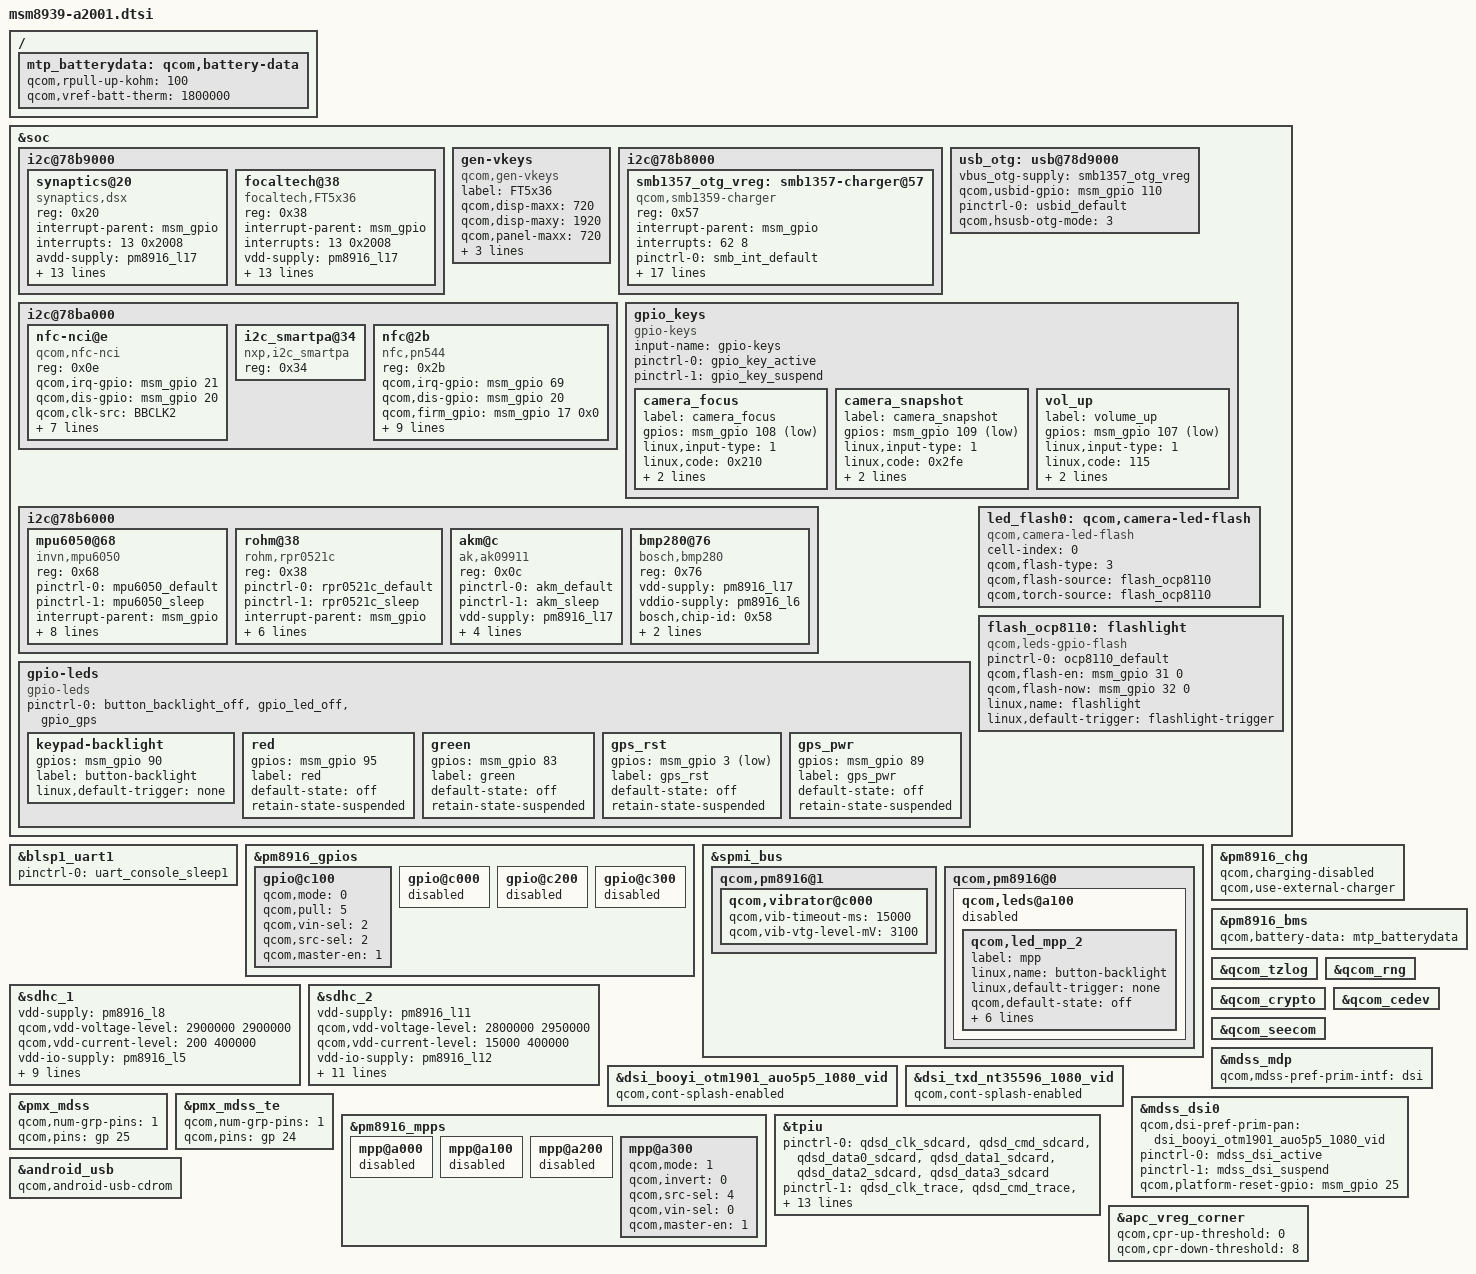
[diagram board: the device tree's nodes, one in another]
/* Copyright (c) 2014-2015, The Linux Foundation. All rights reserved.
 *
 * This program is free software; you can redistribute it and/or modify
 * it under the terms of the GNU General Public License version 2 and
 * only version 2 as published by the Free Software Foundation.
 *
 * This program is distributed in the hope that it will be useful,
 * but WITHOUT ANY WARRANTY; without even the implied warranty of
 * MERCHANTABILITY or FITNESS FOR A PARTICULAR PURPOSE.  See the
 * GNU General Public License for more details.
 */

#include "msm8939-pinctrl-a2001.dtsi"
//#include "msm8939-camera-sensor-mtp.dtsi"
#include "ehang_camera_a2001.dtsi"

&soc {
	i2c@78b9000 { /* BLSP1 QUP5 */
		synaptics@20 {
			compatible = "synaptics,dsx";
			reg = <0x20>;
			interrupt-parent = <&msm_gpio>;
			interrupts = <13 0x2008>;
			avdd-supply = <&pm8916_l17>;
			vdd-supply = <&pm8916_l6>;
			/* pins used by touchscreen */
			pinctrl-names = "pmx_ts_active","pmx_ts_suspend","pmx_ts_suspend";
			pinctrl-0 = <&ts_int_active &ts_reset_active>;
			pinctrl-1 = <&ts_int_suspend &ts_reset_suspend>;
			pinctrl-2 = <&ts_release>;
			synaptics,irq-gpio = <&msm_gpio 13 0x2008>;
			synaptics,reset-gpio = <&msm_gpio 12 0x0>;
			synaptics,i2c-pull-up;
			synaptics,power-down;
			synaptics,disable-gpios;
			synaptics,display-coords = <0 0 1079 1919>;
			synaptics,panel-coords = <0 0 1079 2084>;
			/* Underlying clocks used by secure touch */
			clocks = <&clock_gcc clk_gcc_blsp1_ahb_clk>,
			 <&clock_gcc clk_gcc_blsp1_qup5_i2c_apps_clk>;
			clock-names = "iface_clk", "core_clk";
		};

		focaltech@38 {
			compatible = "focaltech,FT5x36";
			reg = <0x38>;
			interrupt-parent = <&msm_gpio>;
			interrupts = <13 0x2008>;
			vdd-supply = <&pm8916_l17>;
			vcc_i2c-supply = <&pm8916_l6>;
			pinctrl-names = "pmx_ts_active","pmx_ts_suspend";
			pinctrl-0 = <&ts_int_active &ts_reset_active>;
            /*Modified by jiao.shp for tp gesture in 20141113 START*/
            #if 0
			pinctrl-1 = <&ts_int_suspend &ts_reset_suspend>;
            #else
            pinctrl-1 = <&ts_int_active &ts_reset_suspend>;
            #endif
            /*Modified by jiao.shp for tp gesture in 20141113 END*/
			focaltech,family-id = <8>;
			focaltech,max_touch_point = <5>;
			focaltech,reset-gpio = <&msm_gpio 12 0x00>;
			focaltech,irq-gpio = <&msm_gpio 13 0x00>;
			focaltech,display-coords = <0 0 1080 1920>;
			focaltech,panel-coords = <0 0 1080 2020>;
			focaltech,button-map= <139 172 158>;
			focaltech,no-force-update;
			focaltech,i2c-pull-up;
			focaltech,auto_clb;
		};
	};
	gen-vkeys {
		compatible = "qcom,gen-vkeys";
		label = "FT5x36";
		qcom,disp-maxx = <720>;
		qcom,disp-maxy = <1920>;
		qcom,panel-maxx = <720>;
		qcom,panel-maxy = <2080>;
		qcom,key-codes = <139 172 158>;
		qcom,y-offset = <0>;
	};

	// by skj
	i2c@78b8000 {
		smb1357_otg_vreg: smb1357-charger@57 {
			compatible = "qcom,smb1359-charger";
			reg = <0x57>;
			interrupt-parent = <&msm_gpio>;
			interrupts = <62 8>;
			pinctrl-names = "default";
			pinctrl-0 = <&smb_int_default>;

			qcom,bmd-algo-disabled;
			// skj 2005
			qcom,float-voltage-mv = <4200>;
			qcom,charging-timeout = <1536>;
			qcom,recharge-thresh-mv = <100>;
			regulator-name = "smb1357_otg_vreg";
			qcom,soft-vfloat-comp-disabled;
			qcom,thermal-mitigation = <2500 700 600 0>;

			qcom,bms-psy-name = "bms";
			qcom,iterm-disabled;
			qcom,integrated-bms;
			qcom,inhibit-disabled;
			qcom,bms-controlled-charging;
			qcom,chg-vadc = <&pm8916_vadc>;
			qcom,pa-ctrl-pin = <&msm_gpio 93 0>;
			qcom,fastchg-ma= <1500>; 
			
			qcom,dc-psy-type = "Mains";
			qcom,dc-psy-ma = <800>;
			
		};
	};
	// by skj
	usb_otg: usb@78d9000 {
		vbus_otg-supply = <&smb1357_otg_vreg>;
		//vbus_otg-supply = <&pm8916_s1_corner>;
		qcom,usbid-gpio = <&msm_gpio 110 0>;
		pinctrl-names = "default";
		pinctrl-0 = <&usbid_default>;
		qcom,hsusb-otg-mode = <3>;
	};

	i2c@78ba000 { /* BLSP1 QUP6 */
		nfc-nci@e {
			compatible = "qcom,nfc-nci";
			reg = <0x0e>;
			qcom,irq-gpio = <&msm_gpio 21 0x00>;
			qcom,dis-gpio = <&msm_gpio 20 0x00>;
			qcom,clk-src = "BBCLK2";
			interrupt-parent = <&msm_gpio>;
			interrupts = <21 0>;
			interrupt-names = "nfc_irq";
			pinctrl-names = "nfc_active","nfc_suspend";
			pinctrl-0 = <&nfc_int_active &nfc_disable_active>;
			pinctrl-1 = <&nfc_int_suspend &nfc_disable_suspend>;
			qcom,clk-gpio = <&pm8916_gpios 2 0>;
			clocks = <&clock_rpm clk_bb_clk2_pin>;
			clock-names = "ref_clk";
		};
		i2c_smartpa@34 {
			compatible = "nxp,i2c_smartpa";
			reg = <0x34>;
		};
	};
	
	// by skj
	i2c@78ba000 { /* BLSP1 QUP6 */
		nfc@2b {
			compatible = "nfc,pn544";
			reg = <0x2b>;
			qcom,irq-gpio = <&msm_gpio 69 0x00>;
			qcom,dis-gpio = <&msm_gpio 20 0x00>;
			qcom,firm_gpio = <&msm_gpio 17 0x0>;
			qcom,clk-src = "BBCLK2";
			qcom,clk-en-gpio = <&msm_gpio 21 0x00>;
			interrupt-parent = <&msm_gpio>;
			interrupts = <69 0>;
			interrupt-names = "nfc_irq";
			pinctrl-names = "nfc_active","nfc_suspend";
			pinctrl-0 = <&nfc_int_active &nfc_disable_active>;
			pinctrl-1 = <&nfc_int_suspend &nfc_disable_suspend>;
			qcom,clk-gpio = <&pm8916_gpios 2 0>;
			clocks = <&clock_rpm clk_bb_clk2_pin>;
			clock-names = "ref_clk";
			};
	};
	
	
	gpio_keys {
		compatible = "gpio-keys";
		input-name = "gpio-keys";
		pinctrl-names = "tlmm_gpio_key_active","tlmm_gpio_key_suspend";
		pinctrl-0 = <&gpio_key_active>;
		pinctrl-1 = <&gpio_key_suspend>;

		camera_focus {
			label = "camera_focus";
			gpios = <&msm_gpio 108 0x1>;
			linux,input-type = <1>;
			linux,code = <0x210>;
			gpio-key,wakeup;
			debounce-interval = <15>;
		};

		camera_snapshot {
			label = "camera_snapshot";
			gpios = <&msm_gpio 109 0x1>;
			linux,input-type = <1>;
			linux,code = <0x2fe>;
			gpio-key,wakeup;
			debounce-interval = <15>;
		};

		vol_up {
			label = "volume_up";
			gpios = <&msm_gpio 107 0x1>;
			linux,input-type = <1>;
			linux,code = <115>;
			gpio-key,wakeup;
			debounce-interval = <15>;
		};
	};

	i2c@78b6000 { /* BLSP1 QUP2 */
		mpu6050@68 { /* Gyroscope and accelerometer sensor combo */
			compatible = "invn,mpu6050";
			reg = <0x68>;
			pinctrl-names = "mpu_default","mpu_sleep";
			pinctrl-0 = <&mpu6050_default>;
			pinctrl-1 = <&mpu6050_sleep>;
			interrupt-parent = <&msm_gpio>;
			interrupts = <114 0x2>;
			vdd-supply = <&pm8916_l17>;
			vlogic-supply = <&pm8916_l16>;
			vi2c-supply = <&pm8916_l6>;
			invn,use-interrupt;
			invn,gpio-int = <&msm_gpio 114 0x2>;
			invn,place = "Portrait Down Back Side";
			invn,gpio-en = <&msm_gpio 75 0x2>;
		};
		
		rohm@38 { /* Ambient light and proximity sensor */
			compatible = "rohm,rpr0521c";
			reg = <0x38>;
			pinctrl-names = "default","sleep";
			pinctrl-0 = <&rpr0521c_default>;
			pinctrl-1 = <&rpr0521c_sleep>;
			interrupt-parent = <&msm_gpio>;
			interrupts = <113 0x2002>;
			vdd-supply = <&pm8916_l17>;
			vio-supply = <&pm8916_l6>;
			rpr0521c,irq-gpio = <&msm_gpio 113 0x2002>;
			rpr0521c,prox_th_min = <50>;
			rpr0521c,prox_th_max = <150>;
		};

		//avago@39 { /* Ambient light and proximity sensor */
		/*	compatible = "avago,apds9900";
			reg = <0x39>;
			pinctrl-names = "default","sleep";
			pinctrl-0 = <&apds99xx_default>;
			pinctrl-1 = <&apds99xx_sleep>;
			interrupt-parent = <&msm_gpio>;
			interrupts = <113 0x2002>;
			vdd-supply = <&pm8916_l17>;
			vio-supply = <&pm8916_l6>;
			avago,irq-gpio = <&msm_gpio 113 0x2002>;
			avago,ps-threshold = <600>;
			avago,ps-hysteresis-threshold = <500>;
			avago,ps-pulse = <8>;
			avago,ps-pgain = <0>;
			avago,als-B = <186>;
			avago,als-C = <75>;
			avago,als-D = <129>;
			avago,ga-value = <560>;
		};*/
		
		akm@c {
			compatible = "ak,ak09911";
			reg = <0x0c>;
			pinctrl-names = "default","sleep";
			pinctrl-0 = <&akm_default>;
			pinctrl-1 = <&akm_sleep>;
			vdd-supply = <&pm8916_l17>;
			vio-supply = <&pm8916_l6>;
			akm,layout = <0x4>;
			akm,gpio_rstn = <&msm_gpio 36 0x0>;
			akm,auto-report;
		};
		bmp280@76 {
			reg = <0x76>;
			compatible = "bosch,bmp280";
			vdd-supply = <&pm8916_l17>;
			vddio-supply = <&pm8916_l6>;
			bosch,chip-id = <0x58>;
			bosch,oversample = <3>;
			bosch,period = <1000>;
		};

	};
	gpio-leds {
		compatible = "gpio-leds";
		status = "okay";
		pinctrl-names = "default";
		pinctrl-0 = <&button_backlight_off &gpio_led_off &gpio_gps>;

		keypad-backlight {
			gpios = <&msm_gpio 90 0>;
			label = "button-backlight";
			linux,default-trigger = "none";
		};

		red {
			gpios = <&msm_gpio 95 0>;
			label = "red";
			default-state = "off";
			retain-state-suspended;
		};

		green {
			gpios = <&msm_gpio 83 0>;
			label = "green";
			default-state = "off";
			retain-state-suspended;
		};
		// by skj
		gps_rst {
			gpios = <&msm_gpio 3 1>;
			label = "gps_rst";
			default-state = "off";
			retain-state-suspended;
		};			
		gps_pwr {
			gpios = <&msm_gpio 89 0>;
			label = "gps_pwr";
			default-state = "off";
			retain-state-suspended;
		};
	};
};

&blsp1_uart1 {
	status = "ok";
	pinctrl-names = "default";
	pinctrl-0 = <&uart_console_sleep1>;
};

&pm8916_gpios {
	gpio@c100 { /* GPIO 2 */
		/* NFC_CLK_REQ */
		qcom,mode = <0>; /* QPNP_PIN_MODE_DIG_IN */
		qcom,pull = <5>; /* QPNP_PIN_PULL_NO */
		qcom,vin-sel = <2>; /* QPNP_PIN_VIN2 */
		qcom,src-sel = <2>; /* QPNP_PIN_SEL_FUNC_1 */
		qcom,master-en = <1>;
	};
};
&spmi_bus {
	qcom,pm8916@1 {
		qcom,vibrator@c000 {
			status = "okay";
			qcom,vib-timeout-ms = <15000>;
			qcom,vib-vtg-level-mV = <3100>;
		};
	};

	qcom,pm8916@0 {
		qcom,leds@a100 {
			status = "disabled";
			qcom,led_mpp_2 {
				label = "mpp";
				linux,name = "button-backlight";
				linux,default-trigger = "none";
				qcom,default-state = "off";
				qcom,max-current = <40>;
				qcom,current-setting = <5>;
				qcom,id = <6>;
				qcom,mode = "manual";
				qcom,source-sel = <1>;
				qcom,mode-ctrl = <0x60>;
			};
		};
	};
};

&sdhc_1 {
	vdd-supply = <&pm8916_l8>;
	qcom,vdd-voltage-level = <2900000 2900000>;
	qcom,vdd-current-level = <200 400000>;

	vdd-io-supply = <&pm8916_l5>;
	qcom,vdd-io-always-on;
	qcom,vdd-io-lpm-sup;
	qcom,vdd-io-voltage-level = <1800000 1800000>;
	qcom,vdd-io-current-level = <200 60000>;

	pinctrl-names = "active", "sleep";
	pinctrl-0 = <&sdc1_clk_on &sdc1_cmd_on &sdc1_data_on>;
	pinctrl-1 = <&sdc1_clk_off &sdc1_cmd_off &sdc1_data_off>;

	qcom,nonremovable;

	status = "ok";
};

&sdhc_2 {
	vdd-supply = <&pm8916_l11>;
	qcom,vdd-voltage-level = <2800000 2950000>;
	qcom,vdd-current-level = <15000 400000>;

	vdd-io-supply = <&pm8916_l12>;
	qcom,vdd-io-voltage-level = <1800000 2950000>;
	qcom,vdd-io-current-level = <200 50000>;

	pinctrl-names = "active", "sleep";
	pinctrl-0 = <&sdc2_clk_on &sdc2_cmd_on &sdc2_data_on &sdc2_cd_on>;
	pinctrl-1 = <&sdc2_clk_off &sdc2_cmd_off &sdc2_data_off &sdc2_cd_off>;

	#address-cells = <0>;
	interrupt-parent = <&sdhc_2>;
	interrupts = <0 1>; // by skj
	#interrupt-cells = <1>;
	interrupt-map-mask = <0xffffffff>;
	interrupt-map = <0 &intc 0 125 0
			1 &intc 0 221 0>; // by skj
	interrupt-names = "hc_irq", "pwr_irq"; // by skj
	qcom,nonremovable; // by skj

	status = "ok";
};

&pm8916_chg {
	status = "ok";
	qcom,charging-disabled;
	qcom,use-external-charger;
};

/ {
	mtp_batterydata: qcom,battery-data {
		qcom,rpull-up-kohm = <100>;
		qcom,vref-batt-therm = <1800000>;

		#include "batterydata-palladium.dtsi"
	};
};

&pm8916_bms {
	status = "ok";
	qcom,battery-data = <&mtp_batterydata>;
};

&qcom_tzlog {
	status = "okay";
};

&qcom_rng {
	status = "okay";
};

&qcom_crypto {
	status = "okay";
};

&qcom_cedev {
	status = "okay";
};

&qcom_seecom {
	status = "okay";
};

#include  "dsi_panel_nt35596_txd_auo5p5_fhd_video.dtsi"
#include  "dsi_panel_otm1901_booyi_auo5p5_fhd_video.dtsi"

&mdss_mdp {
	qcom,mdss-pref-prim-intf = "dsi";
};

&dsi_booyi_otm1901_auo5p5_1080_vid{
	qcom,cont-splash-enabled;
};

&dsi_txd_nt35596_1080_vid{
	qcom,cont-splash-enabled;
};

&pmx_mdss {
	qcom,num-grp-pins = <1>;
	qcom,pins = <&gp 25>;
};

&pmx_mdss_te {
	qcom,num-grp-pins = <1>;
	qcom,pins = <&gp 24>;
};

&mdss_dsi0 {
	qcom,dsi-pref-prim-pan = <&dsi_booyi_otm1901_auo5p5_1080_vid>;
	pinctrl-names = "mdss_default", "mdss_sleep";
	pinctrl-0 = <&mdss_dsi_active>;
	pinctrl-1 = <&mdss_dsi_suspend>;

	qcom,platform-reset-gpio = <&msm_gpio 25 0>;
};

&pm8916_mpps {
	mpp@a000 { /* MPP 1 */
		/* VDD_PX */
		status = "disabled";
	};

	mpp@a100 { /* MPP 2 */
		/* HR LED */
		status = "disabled";
	};

	mpp@a200 { /* MPP 3 */
		/* VREF DAC */
		status = "disabled";
	};

	mpp@a300 { /* MPP 4 */
		/* Backlight PWM */
		qcom,mode = <1>;		/* Digital output */
		qcom,invert = <0>;		/* Disable invert */
		qcom,src-sel = <4>;		/* DTEST1 */
		qcom,vin-sel = <0>;		/* VPH_PWR */
		qcom,master-en = <1>;		/* Enable MPP */
	};
};

&pm8916_gpios {
	gpio@c000 { /* GPIO 1 */
		/* Battery UICC Alarm */
		status = "disabled";
	};

	gpio@c100 { /* GPIO 2 */
		/* NFC_CLK_REQ */
		qcom,mode = <0>; /* QPNP_PIN_MODE_DIG_IN */
		qcom,pull = <5>; /* QPNP_PIN_PULL_NO */
		qcom,vin-sel = <2>; /* QPNP_PIN_VIN2 */
		qcom,src-sel = <2>; /* QPNP_PIN_SEL_FUNC_1 */
		qcom,master-en = <1>;
	};

	gpio@c200 { /* GPIO 3 */
		/* External regulator control for WTR */
		status = "disabled";
	};

	gpio@c300 { /* GPIO 4 */
		/* External regulator control for APC */
		status = "disabled";
	};
};

/* CoreSight */
&tpiu {
	pinctrl-names = "sdcard", "trace", "swduart",
			"swdtrc", "jtag", "spmi";
	/* NIDnT */
	pinctrl-0 = <&qdsd_clk_sdcard &qdsd_cmd_sdcard
		     &qdsd_data0_sdcard &qdsd_data1_sdcard
		     &qdsd_data2_sdcard &qdsd_data3_sdcard>;
	pinctrl-1 = <&qdsd_clk_trace &qdsd_cmd_trace
		     &qdsd_data0_trace &qdsd_data1_trace
		     &qdsd_data2_trace &qdsd_data3_trace>;
	pinctrl-2 = <&qdsd_cmd_swduart &qdsd_data0_swduart
		     &qdsd_data1_swduart &qdsd_data2_swduart
		     &qdsd_data3_swduart>;
	pinctrl-3 = <&qdsd_clk_swdtrc &qdsd_cmd_swdtrc
		     &qdsd_data0_swdtrc &qdsd_data1_swdtrc
		     &qdsd_data2_swdtrc &qdsd_data3_swdtrc>;
	pinctrl-4 = <&qdsd_cmd_jtag &qdsd_data0_jtag
		     &qdsd_data1_jtag &qdsd_data2_jtag
		     &qdsd_data3_jtag>;
	pinctrl-5 = <&qdsd_clk_spmi &qdsd_cmd_spmi
		     &qdsd_data0_spmi &qdsd_data3_spmi>;
};

/* add by shengwegiuang for usb */
&android_usb {
	qcom,android-usb-cdrom;
};
/* add by shengweiguang for usb end */

&apc_vreg_corner {
		qcom,cpr-up-threshold = <0>;
		qcom,cpr-down-threshold = <8>;
};

&soc {
	led_flash0: qcom,camera-led-flash {
		cell-index = <0>;
		compatible = "qcom,camera-led-flash";
		qcom,flash-type = <3>;
		qcom,flash-source = <&flash_ocp8110>;
		qcom,torch-source = <&flash_ocp8110>;
	};
	flash_ocp8110:flashlight {
		compatible = "qcom,leds-gpio-flash";
		status = "okay";
		pinctrl-names = "ocp8110_default";
		pinctrl-0 = <&ocp8110_default>;
		qcom,flash-en = <&msm_gpio 31 0>;
		qcom,flash-now = <&msm_gpio 32 0>;
		linux,name = "flashlight";
		linux,default-trigger = "flashlight-trigger";
	};
};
